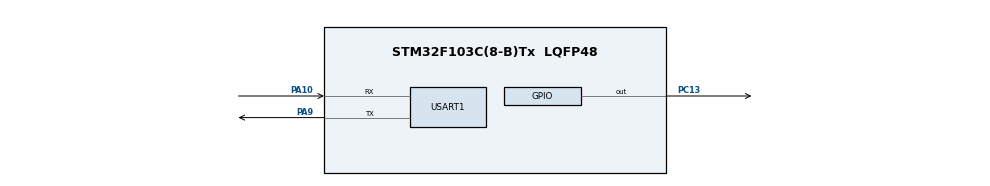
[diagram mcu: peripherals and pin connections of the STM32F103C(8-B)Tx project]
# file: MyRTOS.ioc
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Mcu.Family=STM32F1
Mcu.Name=STM32F103C(8-B)Tx
Mcu.Package=LQFP48
NVIC.PriorityGroup=NVIC_PRIORITYGROUP_4
NVIC.TIM4_IRQn=true\:15\:0\:false\:false\:true\:false\:true\:true
NVIC.TimeBase=TIM4_IRQn
NVIC.TimeBaseIP=TIM4
PA10.GPIO_PuPd=GPIO_NOPULL
PA10.Mode=Asynchronous
PA10.Signal=USART1_RX
PA13.Mode=Serial_Wire
PA13.Signal=SYS_JTMS-SWDIO
PA14.Mode=Serial_Wire
PA14.Signal=SYS_JTCK-SWCLK
PA9.Mode=Asynchronous
PA9.Signal=USART1_TX
PC13-TAMPER-RTC.Signal=GPIO_Output
ProjectManager.HeapSize=0x200
ProjectManager.StackSize=0x400
ProjectManager.TargetToolchain=STM32CubeIDE
RCC.APB1Freq_Value=8000000
RCC.APB2Freq_Value=8000000
USART1.VirtualMode=VM_ASYNC
VP_SYS_VS_tim4.Mode=TIM4
board=custom

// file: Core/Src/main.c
/* USER CODE BEGIN Header */
/**
  ******************************************************************************
  * @file           : main.c
  * @brief          : Main program body
  ******************************************************************************
  * @attention
  *
  * Copyright (c) 2024 STMicroelectronics.
  * All rights reserved.
  *
  * This software is licensed under terms that can be found in the LICENSE file
  * in the root directory of this software component.
  * If no LICENSE file comes with this software, it is provided AS-IS.
  *
  ******************************************************************************
  */
/* USER CODE END Header */
#include "main.h"
#include "usart.h"
#include "gpio.h"

/* USER CODE BEGIN Includes */
#include "MyRTOS.h"

/* USER CODE END Includes */

/* USER CODE BEGIN PV */
tTask * currentTask;
tTask * nextTask;
tBitmap taskPrioBitmap;
tList taskTable[MYRTOS_PRO_COUNT];

uint8_t schedLockCount;
tList tTaskDelayedList;

tTask tTaskIdle;
tTaskStack taskIdleEnv[128];

/* USER CODE END PV */

void SystemClock_Config(void);

/* USER CODE BEGIN 0 */

void idleTaskEntry(void * param) {
  while(1) {

  }
}

/* USER CODE END 0 */

int main(void)
{

  /* MCU Configuration--------------------------------------------------------*/

  /* Reset of all peripherals, Initializes the Flash interface and the Systick. */
  HAL_Init();

  /* Configure the system clock */
  SystemClock_Config();

  /* Initialize all configured peripherals */
  MX_GPIO_Init();
  MX_USART1_UART_Init();
  /* USER CODE BEGIN 2 */
  tTaskSchedInit();

  tTaskDelayListInit();

  tTimerModuleInit();

  tInitApp();

  tTaskInit(&tTaskIdle, idleTaskEntry, (void *)0, MYRTOS_PRO_COUNT - 1, &taskIdleEnv[MTRTOS_IDLETASK_STACK_SIZE]);

  nextTask = tTaskHighestReady();

  tTaskRunFirst();

  /* USER CODE END 2 */

  /* Infinite loop */
  while (1)
  {

    /* USER CODE BEGIN 3 */
    // HAL_UART_Transmit(&huart1, (uint8_t *)"Hello World!\r\n", 14, 1000);
    // HAL_GPIO_TogglePin(GPIOC, GPIO_PIN_13);
    HAL_Delay(1000);
    break;

  }
  /* USER CODE END 3 */
}

void SystemClock_Config(void)
{
  RCC_OscInitTypeDef RCC_OscInitStruct = {0};
  RCC_ClkInitTypeDef RCC_ClkInitStruct = {0};

  /** Initializes the RCC Oscillators according to the specified parameters
  * in the RCC_OscInitTypeDef structure.
  */
  RCC_OscInitStruct.OscillatorType = RCC_OSCILLATORTYPE_HSI;
  RCC_OscInitStruct.HSIState = RCC_HSI_ON;
  RCC_OscInitStruct.HSICalibrationValue = RCC_HSICALIBRATION_DEFAULT;
  RCC_OscInitStruct.PLL.PLLState = RCC_PLL_NONE;
  if (HAL_RCC_OscConfig(&RCC_OscInitStruct) != HAL_OK)
  {
    Error_Handler();
  }

  /** Initializes the CPU, AHB and APB buses clocks
  */
  RCC_ClkInitStruct.ClockType = RCC_CLOCKTYPE_HCLK|RCC_CLOCKTYPE_SYSCLK
                              |RCC_CLOCKTYPE_PCLK1|RCC_CLOCKTYPE_PCLK2;
  RCC_ClkInitStruct.SYSCLKSource = RCC_SYSCLKSOURCE_HSI;
  RCC_ClkInitStruct.AHBCLKDivider = RCC_SYSCLK_DIV1;
  RCC_ClkInitStruct.APB1CLKDivider = RCC_HCLK_DIV1;
  RCC_ClkInitStruct.APB2CLKDivider = RCC_HCLK_DIV1;

  if (HAL_RCC_ClockConfig(&RCC_ClkInitStruct, FLASH_LATENCY_0) != HAL_OK)
  {
    Error_Handler();
  }
}

void HAL_TIM_PeriodElapsedCallback(TIM_HandleTypeDef *htim)
{
  if (htim->Instance == TIM4) {
    HAL_IncTick();
  }
}

void Error_Handler(void)
{
  __disable_irq();
  while (1)
  {
  }
}
